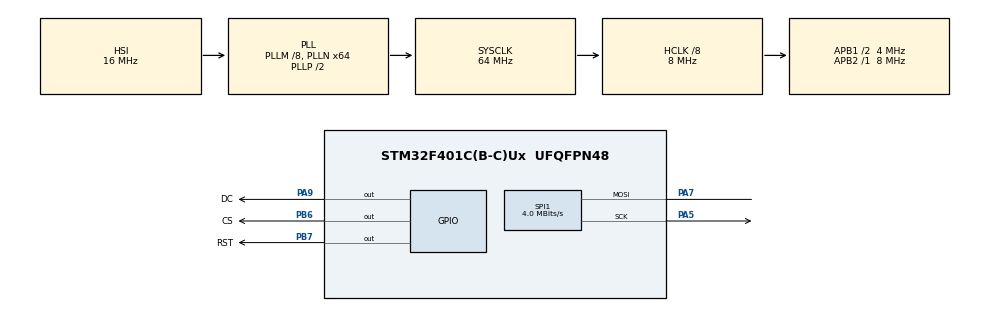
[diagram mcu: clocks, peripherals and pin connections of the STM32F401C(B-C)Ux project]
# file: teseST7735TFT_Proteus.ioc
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Mcu.Family=STM32F4
Mcu.Name=STM32F401C(B-C)Ux
Mcu.Package=UFQFPN48
NVIC.PriorityGroup=NVIC_PRIORITYGROUP_4
PA5.Mode=Simplex_Bidirectional_Master
PA5.Signal=SPI1_SCK
PA7.Mode=Simplex_Bidirectional_Master
PA7.Signal=SPI1_MOSI
PA9.GPIO_Label=DC
PA9.Signal=GPIO_Output
PB6.GPIO_Label=CS
PB6.Signal=GPIO_Output
PB7.GPIO_Label=RST
PB7.Signal=GPIO_Output
ProjectManager.HeapSize=0x200
ProjectManager.StackSize=0x400
ProjectManager.TargetToolchain=STM32CubeIDE
RCC.48MHZClocksFreq_Value=32000000
RCC.AHBCLKDivider=RCC_SYSCLK_DIV8
RCC.AHBFreq_Value=8000000
RCC.APB1CLKDivider=RCC_HCLK_DIV2
RCC.APB1Freq_Value=4000000
RCC.APB1TimFreq_Value=8000000
RCC.APB2Freq_Value=8000000
RCC.APB2TimFreq_Value=8000000
RCC.CortexFreq_Value=8000000
RCC.HCLKFreq_Value=8000000
RCC.HSE_VALUE=25000000
RCC.HSI_VALUE=16000000
RCC.LSE_VALUE=32768
RCC.PLLM=8
RCC.PLLN=64
RCC.SYSCLKFreq_VALUE=64000000
RCC.SYSCLKSource=RCC_SYSCLKSOURCE_PLLCLK
RCC.VCOOutputFreq_Value=128000000
SPI1.BaudRatePrescaler=SPI_BAUDRATEPRESCALER_2
SPI1.CLKPolarity=SPI_POLARITY_HIGH
SPI1.CalculateBaudRate=4.0 MBits/s
SPI1.Direction=SPI_DIRECTION_1LINE
SPI1.Mode=SPI_MODE_MASTER
SPI1.VirtualType=VM_MASTER
board=custom

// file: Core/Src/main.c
/* USER CODE BEGIN Header */
/**
  ******************************************************************************
  * @file           : main.c
  * @brief          : Main program body
  ******************************************************************************
  * @attention
  *
  * Copyright (c) 2025 STMicroelectronics.
  * All rights reserved.
  *
  * This software is licensed under terms that can be found in the LICENSE file
  * in the root directory of this software component.
  * If no LICENSE file comes with this software, it is provided AS-IS.
  *
  ******************************************************************************
  */
/* USER CODE END Header */
#include "main.h"
#include "spi.h"
#include "gpio.h"

/* USER CODE BEGIN Includes */
#include <string.h>
#include "fonts.h"

#include "st7735.h"
//#include "testimg.h"
/* USER CODE END Includes */

void SystemClock_Config(void);

int main(void)
{

  /* MCU Configuration--------------------------------------------------------*/

  /* Reset of all peripherals, Initializes the Flash interface and the Systick. */
  HAL_Init();

  /* Configure the system clock */
  SystemClock_Config();

  /* Initialize all configured peripherals */
  MX_GPIO_Init();
  MX_SPI1_Init();
  /* USER CODE BEGIN 2 */
  ST7735_Init();
  HAL_Delay(100);
  ST7735_FillScreen(0xFEA0);
  ST7735_WriteString(10, 10, "Hi Iam Amer from ALEBEL company", Font_11x18, ST7735_CYAN, ST7735_BLUE);
  /* USER CODE END 2 */

  /* Infinite loop */
  while (1)
  {

  }
}

void SystemClock_Config(void)
{
  RCC_OscInitTypeDef RCC_OscInitStruct = {0};
  RCC_ClkInitTypeDef RCC_ClkInitStruct = {0};

  /** Configure the main internal regulator output voltage
  */
  __HAL_RCC_PWR_CLK_ENABLE();
  __HAL_PWR_VOLTAGESCALING_CONFIG(PWR_REGULATOR_VOLTAGE_SCALE2);

  /** Initializes the RCC Oscillators according to the specified parameters
  * in the RCC_OscInitTypeDef structure.
  */
  RCC_OscInitStruct.OscillatorType = RCC_OSCILLATORTYPE_HSI;
  RCC_OscInitStruct.HSIState = RCC_HSI_ON;
  RCC_OscInitStruct.HSICalibrationValue = RCC_HSICALIBRATION_DEFAULT;
  RCC_OscInitStruct.PLL.PLLState = RCC_PLL_ON;
  RCC_OscInitStruct.PLL.PLLSource = RCC_PLLSOURCE_HSI;
  RCC_OscInitStruct.PLL.PLLM = 8;
  RCC_OscInitStruct.PLL.PLLN = 64;
  RCC_OscInitStruct.PLL.PLLP = RCC_PLLP_DIV2;
  RCC_OscInitStruct.PLL.PLLQ = 4;
  if (HAL_RCC_OscConfig(&RCC_OscInitStruct) != HAL_OK)
  {
    Error_Handler();
  }

  /** Initializes the CPU, AHB and APB buses clocks
  */
  RCC_ClkInitStruct.ClockType = RCC_CLOCKTYPE_HCLK|RCC_CLOCKTYPE_SYSCLK
                              |RCC_CLOCKTYPE_PCLK1|RCC_CLOCKTYPE_PCLK2;
  RCC_ClkInitStruct.SYSCLKSource = RCC_SYSCLKSOURCE_PLLCLK;
  RCC_ClkInitStruct.AHBCLKDivider = RCC_SYSCLK_DIV8;
  RCC_ClkInitStruct.APB1CLKDivider = RCC_HCLK_DIV2;
  RCC_ClkInitStruct.APB2CLKDivider = RCC_HCLK_DIV1;

  if (HAL_RCC_ClockConfig(&RCC_ClkInitStruct, FLASH_LATENCY_0) != HAL_OK)
  {
    Error_Handler();
  }
}

void Error_Handler(void)
{
  __disable_irq();
  while (1)
  {
  }
}
